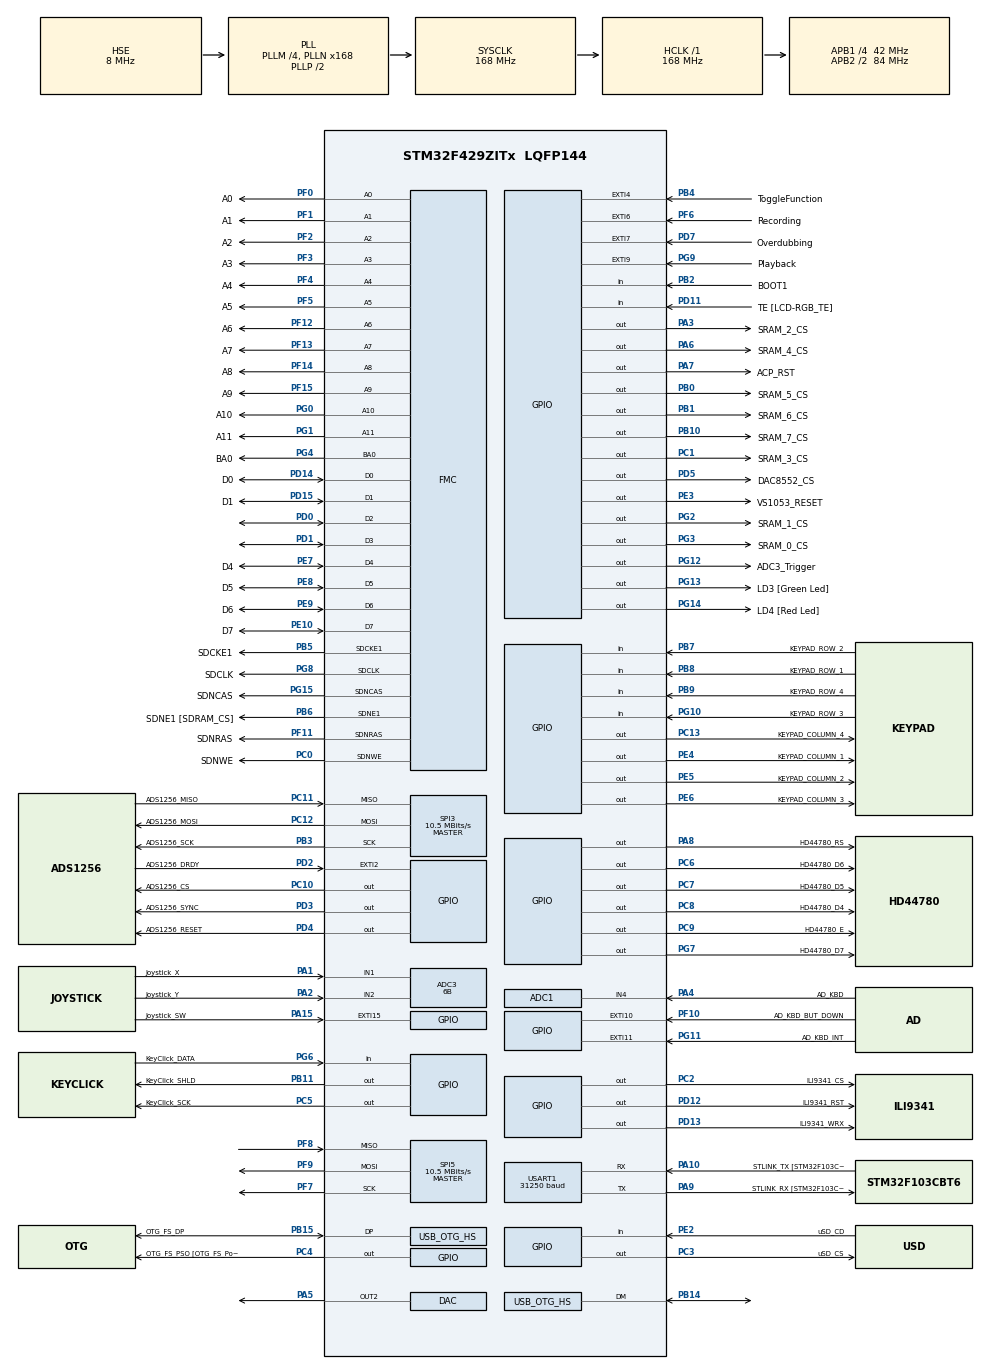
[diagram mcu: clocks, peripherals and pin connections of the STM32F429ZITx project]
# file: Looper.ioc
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ADC1.Channel-0\#ChannelRegularConversion=ADC_CHANNEL_4
ADC1.ClockPrescaler=ADC_CLOCK_SYNC_PCLK_DIV4
ADC1.ContinuousConvMode=DISABLE
ADC1.DMAContinuousRequests=DISABLE
ADC1.DataAlign=ADC_DATAALIGN_RIGHT
ADC1.DiscontinuousConvMode=DISABLE
ADC1.EOCSelection=ADC_EOC_SINGLE_CONV
ADC1.EnableAnalogWatchDog=false
ADC1.ExternalTrigConv=ADC_EXTERNALTRIGCONV_Ext_IT11
ADC1.ExternalTrigConvEdge=ADC_EXTERNALTRIGCONVEDGE_RISING
ADC1.InjNumberOfConversion=0
ADC1.NbrOfConversion=1
ADC1.NbrOfConversionFlag=1
ADC1.Rank-0\#ChannelRegularConversion=1
ADC1.Resolution=ADC_RESOLUTION_6B
ADC1.SamplingTime-0\#ChannelRegularConversion=ADC_SAMPLETIME_480CYCLES
ADC1.ScanConvMode=DISABLE
ADC1.master=1
ADC3.Channel-50\#ChannelRegularConversion=ADC_CHANNEL_1
ADC3.Channel-51\#ChannelRegularConversion=ADC_CHANNEL_2
ADC3.ClockPrescaler=ADC_CLOCK_SYNC_PCLK_DIV4
ADC3.ContinuousConvMode=ENABLE
ADC3.DMAContinuousRequests=ENABLE
ADC3.DataAlign=ADC_DATAALIGN_RIGHT
ADC3.DiscontinuousConvMode=DISABLE
ADC3.EOCSelection=ADC_EOC_SEQ_CONV
ADC3.EnableAnalogWatchDog=false
ADC3.ExternalTrigConv=ADC_SOFTWARE_START
ADC3.ExternalTrigConvEdge=ADC_EXTERNALTRIGCONVEDGE_NONE
ADC3.InjNumberOfConversion=0
ADC3.NbrOfConversion=2
ADC3.NbrOfConversionFlag=1
ADC3.Rank-50\#ChannelRegularConversion=1
ADC3.Rank-51\#ChannelRegularConversion=2
ADC3.Resolution=ADC_RESOLUTION_6B
ADC3.SamplingTime-50\#ChannelRegularConversion=ADC_SAMPLETIME_144CYCLES
ADC3.SamplingTime-51\#ChannelRegularConversion=ADC_SAMPLETIME_144CYCLES
ADC3.ScanConvMode=ENABLE
DAC.DAC_Trigger2=DAC_TRIGGER_T8_TRGO
Dma.ADC3.3.Direction=DMA_PERIPH_TO_MEMORY
Dma.ADC3.3.FIFOMode=DMA_FIFOMODE_DISABLE
Dma.ADC3.3.Instance=DMA2_Stream1
Dma.ADC3.3.MemDataAlignment=DMA_MDATAALIGN_WORD
Dma.ADC3.3.MemInc=DMA_MINC_ENABLE
Dma.ADC3.3.Mode=DMA_CIRCULAR
Dma.ADC3.3.PeriphDataAlignment=DMA_PDATAALIGN_WORD
Dma.ADC3.3.PeriphInc=DMA_PINC_DISABLE
Dma.ADC3.3.Priority=DMA_PRIORITY_MEDIUM
Dma.DAC2.0.Direction=DMA_MEMORY_TO_PERIPH
Dma.DAC2.0.FIFOMode=DMA_FIFOMODE_DISABLE
Dma.DAC2.0.Instance=DMA1_Stream6
Dma.DAC2.0.MemDataAlignment=DMA_MDATAALIGN_HALFWORD
Dma.DAC2.0.MemInc=DMA_MINC_ENABLE
Dma.DAC2.0.Mode=DMA_CIRCULAR
Dma.DAC2.0.PeriphDataAlignment=DMA_PDATAALIGN_HALFWORD
Dma.DAC2.0.PeriphInc=DMA_PINC_DISABLE
Dma.DAC2.0.Priority=DMA_PRIORITY_HIGH
Dma.Request0=DAC2
Dma.Request1=SPI5_RX
Dma.Request2=SPI5_TX
Dma.Request3=ADC3
Dma.SPI5_RX.1.Direction=DMA_PERIPH_TO_MEMORY
Dma.SPI5_RX.1.FIFOMode=DMA_FIFOMODE_ENABLE
Dma.SPI5_RX.1.FIFOThreshold=DMA_FIFO_THRESHOLD_1QUARTERFULL
Dma.SPI5_RX.1.Instance=DMA2_Stream3
Dma.SPI5_RX.1.MemBurst=DMA_MBURST_SINGLE
Dma.SPI5_RX.1.MemDataAlignment=DMA_MDATAALIGN_BYTE
Dma.SPI5_RX.1.MemInc=DMA_MINC_ENABLE
Dma.SPI5_RX.1.Mode=DMA_NORMAL
Dma.SPI5_RX.1.PeriphBurst=DMA_PBURST_SINGLE
Dma.SPI5_RX.1.PeriphDataAlignment=DMA_PDATAALIGN_BYTE
Dma.SPI5_RX.1.PeriphInc=DMA_PINC_DISABLE
Dma.SPI5_RX.1.Priority=DMA_PRIORITY_MEDIUM
Dma.SPI5_TX.2.Direction=DMA_MEMORY_TO_PERIPH
Dma.SPI5_TX.2.FIFOMode=DMA_FIFOMODE_ENABLE
Dma.SPI5_TX.2.FIFOThreshold=DMA_FIFO_THRESHOLD_1QUARTERFULL
Dma.SPI5_TX.2.Instance=DMA2_Stream4
Dma.SPI5_TX.2.MemBurst=DMA_MBURST_SINGLE
Dma.SPI5_TX.2.MemDataAlignment=DMA_MDATAALIGN_BYTE
Dma.SPI5_TX.2.MemInc=DMA_MINC_ENABLE
Dma.SPI5_TX.2.Mode=DMA_NORMAL
Dma.SPI5_TX.2.PeriphBurst=DMA_PBURST_SINGLE
Dma.SPI5_TX.2.PeriphDataAlignment=DMA_PDATAALIGN_BYTE
Dma.SPI5_TX.2.PeriphInc=DMA_PINC_DISABLE
Dma.SPI5_TX.2.Priority=DMA_PRIORITY_MEDIUM
Mcu.Family=STM32F4
Mcu.Name=STM32F429ZITx
Mcu.Package=LQFP144
NVIC.ADC_IRQn=true\:3\:0\:true\:false\:true\:true
NVIC.DMA1_Stream6_IRQn=true\:1\:2\:true\:false\:true\:false
NVIC.DMA2_Stream1_IRQn=true\:1\:3\:true\:false\:true\:false
NVIC.DMA2_Stream3_IRQn=true\:3\:0\:true\:false\:true\:false
NVIC.DMA2_Stream4_IRQn=true\:3\:2\:true\:false\:true\:false
NVIC.EXTI15_10_IRQn=true\:0\:1\:false\:false\:true\:true
NVIC.EXTI2_IRQn=true\:0\:1\:true\:false\:true\:true
NVIC.EXTI4_IRQn=true\:2\:3\:true\:false\:true\:true
NVIC.EXTI9_5_IRQn=true\:2\:3\:true\:false\:true\:true
NVIC.OTG_HS_IRQn=true\:0\:0\:false\:false\:true\:false
NVIC.PVD_IRQn=true\:0\:0\:false\:false\:true\:true
NVIC.PriorityGroup=NVIC_PRIORITYGROUP_2
NVIC.TIM1_BRK_TIM9_IRQn=true\:2\:2\:true\:false\:true\:true
NVIC.TIM2_IRQn=true\:3\:2\:true\:false\:true\:true
NVIC.TIM4_IRQn=true\:3\:3\:true\:false\:true\:true
NVIC.TIM8_UP_TIM13_IRQn=true\:0\:0\:false\:false\:true\:true
PA1.GPIO_Label=Joystick_X
PA1.Signal=ADCx_IN1
PA10.GPIO_Label=STLINK_TX [STM32F103CBT6_PA2]
PA10.Mode=Multiprocessor_communication
PA10.Signal=USART1_RX
PA11.GPIO_Speed=GPIO_SPEED_FREQ_HIGH
PA11.Signal=USB_OTG_FS_DM
PA13.GPIO_Label=SWDIO
PA13.Signal=SYS_JTMS-SWDIO
PA14.GPIO_Label=SWCLK
PA14.Signal=SYS_JTCK-SWCLK
PA15.GPIO_Label=Joystick_SW
PA15.GPIO_ModeDefaultEXTI=GPIO_MODE_IT_FALLING
PA15.Signal=GPXTI15
PA2.GPIO_Label=Joystick_Y
PA2.Signal=ADCx_IN2
PA3.GPIO_Label=SRAM_2_CS
PA3.GPIO_Speed=GPIO_SPEED_FREQ_HIGH
PA3.PinState=GPIO_PIN_SET
PA3.Signal=GPIO_Output
PA4.GPIO_Label=AD_KBD
PA4.Signal=ADCx_IN4
PA5.Signal=COMP_DAC2_group
PA6.GPIO_Label=SRAM_4_CS
PA6.GPIO_Speed=GPIO_SPEED_FREQ_HIGH
PA6.PinState=GPIO_PIN_SET
PA6.Signal=GPIO_Output
PA7.GPIO_Label=ACP_RST
PA7.GPIO_Mode=GPIO_MODE_OUTPUT_PP
PA7.GPIO_PuPd=GPIO_NOPULL
PA7.GPIO_Speed=GPIO_SPEED_FREQ_LOW
PA7.Signal=GPIO_Output
PA8.GPIO_Label=HD44780_RS
PA8.GPIO_Speed=GPIO_SPEED_FREQ_MEDIUM
PA8.PinState=GPIO_PIN_SET
PA8.Signal=GPIO_Output
PA9.GPIO_Label=STLINK_RX [STM32F103CBT6_PA3]
PA9.Mode=Multiprocessor_communication
PA9.Signal=USART1_TX
PB0.GPIO_Label=SRAM_5_CS
PB0.GPIO_Speed=GPIO_SPEED_FREQ_HIGH
PB0.PinState=GPIO_PIN_SET
PB0.Signal=GPIO_Output
PB1.GPIO_Label=SRAM_6_CS
PB1.GPIO_Speed=GPIO_SPEED_FREQ_HIGH
PB1.PinState=GPIO_PIN_SET
PB1.Signal=GPIO_Output
PB10.GPIO_Label=SRAM_7_CS
PB10.GPIO_Speed=GPIO_SPEED_FREQ_HIGH
PB10.PinState=GPIO_PIN_SET
PB10.Signal=GPIO_Output
PB11.GPIO_Label=KeyClick_SHLD
PB11.Signal=GPIO_Output
PB12.GPIO_Label=OTG_FS_ID
PB12.GPIO_Mode=GPIO_MODE_AF_PP
PB12.GPIO_PuPd=GPIO_NOPULL
PB12.GPIO_Speed=GPIO_SPEED_FREQ_LOW
PB12.Signal=USB_OTG_HS_ID
PB13.GPIO_Label=VBUS_FS
PB13.GPIO_Mode=GPIO_MODE_INPUT
PB13.GPIO_PuPd=GPIO_NOPULL
PB13.Signal=USB_OTG_HS_VBUS
PB14.Mode=Device_Only_FS
PB14.Signal=USB_OTG_HS_DM
PB15.GPIO_Label=OTG_FS_DP
PB15.GPIO_Mode=GPIO_MODE_AF_PP
PB15.GPIO_PuPd=GPIO_NOPULL
PB15.GPIO_Speed=GPIO_SPEED_FREQ_LOW
PB15.Mode=Device_Only_FS
PB15.Signal=USB_OTG_HS_DP
PB2/BOOT1.GPIO_Label=BOOT1
PB2/BOOT1.GPIO_Mode=GPIO_MODE_INPUT
PB2/BOOT1.GPIO_PuPd=GPIO_NOPULL
PB2/BOOT1.Signal=GPIO_Input
PB3.GPIO_Label=ADS1256_SCK
PB3.GPIO_Speed=GPIO_SPEED_FREQ_VERY_HIGH
PB3.Mode=Full_Duplex_Master
PB3.Signal=SPI3_SCK
PB4.GPIO_Label=ToggleFunction
PB4.GPIO_ModeDefaultEXTI=GPIO_MODE_IT_FALLING
PB4.Signal=GPXTI4
PB5.GPIO_Label=SDCKE1
PB5.GPIO_Mode=GPIO_MODE_AF_PP
PB5.GPIO_PuPd=GPIO_NOPULL
PB5.GPIO_Speed=GPIO_SPEED_FREQ_VERY_HIGH
PB5.Mode=SdramChipSelect2_2
PB5.Signal=FMC_SDCKE1
PB6.GPIO_Label=SDNE1 [SDRAM_CS]
PB6.GPIO_Mode=GPIO_MODE_AF_PP
PB6.GPIO_PuPd=GPIO_NOPULL
PB6.GPIO_Speed=GPIO_SPEED_FREQ_VERY_HIGH
PB6.Mode=SdramChipSelect2_2
PB6.Signal=FMC_SDNE1
PB7.GPIO_Label=KEYPAD_ROW_2
PB7.GPIO_PuPd=GPIO_PULLUP
PB7.Signal=GPIO_Input
PB8.GPIO_Label=KEYPAD_ROW_1
PB8.GPIO_PuPd=GPIO_PULLUP
PB8.Signal=GPIO_Input
PB9.GPIO_Label=KEYPAD_ROW_4
PB9.GPIO_PuPd=GPIO_PULLUP
PB9.Signal=GPIO_Input
PC0.GPIO_Label=SDNWE
PC0.GPIO_Mode=GPIO_MODE_AF_PP
PC0.GPIO_PuPd=GPIO_NOPULL
PC0.GPIO_Speed=GPIO_SPEED_FREQ_VERY_HIGH
PC0.Signal=FMC_SDNWE
PC1.GPIO_Label=SRAM_3_CS
PC1.Signal=GPIO_Output
PC10.GPIO_Label=ADS1256_CS
PC10.GPIO_Speed=GPIO_SPEED_FREQ_HIGH
PC10.PinState=GPIO_PIN_SET
PC10.Signal=GPIO_Output
PC11.GPIO_Label=ADS1256_MISO
PC11.GPIO_Speed=GPIO_SPEED_FREQ_VERY_HIGH
PC11.Mode=Full_Duplex_Master
PC11.Signal=SPI3_MISO
PC12.GPIO_Label=ADS1256_MOSI
PC12.GPIO_Speed=GPIO_SPEED_FREQ_VERY_HIGH
PC12.Mode=Full_Duplex_Master
PC12.Signal=SPI3_MOSI
PC13.GPIO_Label=KEYPAD_COLUMN_4
PC13.Signal=GPIO_Output
PC14/OSC32_IN.GPIO_Label=PC14-OSC32_IN
PC14/OSC32_IN.Signal=RCC_OSC32_IN
PC15/OSC32_OUT.GPIO_Label=PC15-OSC32_OUT
PC15/OSC32_OUT.Signal=RCC_OSC32_OUT
PC2.GPIO_Label=ILI9341_CS
PC2.Signal=GPIO_Output
PC3.GPIO_Label=uSD_CS
PC3.GPIO_Speed=GPIO_SPEED_FREQ_HIGH
PC3.PinState=GPIO_PIN_SET
PC3.Signal=GPIO_Output
PC4.GPIO_Label=OTG_FS_PSO [OTG_FS_PowerSwitchOn]
PC4.GPIO_Mode=GPIO_MODE_OUTPUT_PP
PC4.GPIO_PuPd=GPIO_NOPULL
PC4.GPIO_Speed=GPIO_SPEED_FREQ_LOW
PC4.Signal=GPIO_Output
PC5.GPIO_Label=KeyClick_SCK
PC5.GPIO_Speed=GPIO_SPEED_FREQ_HIGH
PC5.PinState=GPIO_PIN_SET
PC5.Signal=GPIO_Output
PC6.GPIO_Label=HD44780_D6
PC6.GPIO_Speed=GPIO_SPEED_FREQ_MEDIUM
PC6.PinState=GPIO_PIN_SET
PC6.Signal=GPIO_Output
PC7.GPIO_Label=HD44780_D5
PC7.GPIO_Speed=GPIO_SPEED_FREQ_MEDIUM
PC7.PinState=GPIO_PIN_SET
PC7.Signal=GPIO_Output
PC8.GPIO_Label=HD44780_D4
PC8.GPIO_Speed=GPIO_SPEED_FREQ_MEDIUM
PC8.PinState=GPIO_PIN_SET
PC8.Signal=GPIO_Output
PC9.GPIO_Label=HD44780_E
PC9.GPIO_Speed=GPIO_SPEED_FREQ_MEDIUM
PC9.PinState=GPIO_PIN_SET
PC9.Signal=GPIO_Output
PD0.Signal=FMC_D2_DA2
PD1.Signal=FMC_D3_DA3
PD10.GPIO_Label=D15
PD10.GPIO_Mode=GPIO_MODE_AF_PP
PD10.GPIO_PuPd=GPIO_NOPULL
PD10.GPIO_Speed=GPIO_SPEED_FREQ_VERY_HIGH
PD10.Signal=FMC_D15_DA15
PD11.GPIO_Label=TE [LCD-RGB_TE]
PD11.GPIO_Mode=GPIO_MODE_INPUT
PD11.GPIO_PuPd=GPIO_NOPULL
PD11.Signal=GPIO_Input
PD12.GPIO_Label=ILI9341_RST
PD12.GPIO_Mode=GPIO_MODE_OUTPUT_PP
PD12.GPIO_PuPd=GPIO_NOPULL
PD12.GPIO_Speed=GPIO_SPEED_FREQ_LOW
PD12.Signal=GPIO_Output
PD13.GPIO_Label=ILI9341_WRX
PD13.GPIO_Mode=GPIO_MODE_OUTPUT_PP
PD13.GPIO_PuPd=GPIO_NOPULL
PD13.GPIO_Speed=GPIO_SPEED_FREQ_LOW
PD13.Signal=GPIO_Output
PD14.GPIO_Label=D0
PD14.GPIO_Mode=GPIO_MODE_AF_PP
PD14.GPIO_PuPd=GPIO_NOPULL
PD14.GPIO_Speed=GPIO_SPEED_FREQ_VERY_HIGH
PD14.Signal=FMC_D0_DA0
PD15.GPIO_Label=D1
PD15.GPIO_Mode=GPIO_MODE_AF_PP
PD15.GPIO_PuPd=GPIO_NOPULL
PD15.GPIO_Speed=GPIO_SPEED_FREQ_VERY_HIGH
PD15.Signal=FMC_D1_DA1
PD2.GPIO_Label=ADS1256_DRDY
PD2.GPIO_ModeDefaultEXTI=GPIO_MODE_IT_FALLING
PD2.GPIO_PuPd=GPIO_PULLUP
PD2.Signal=GPXTI2
PD3.GPIO_Label=ADS1256_SYNC
PD3.GPIO_Speed=GPIO_SPEED_FREQ_HIGH
PD3.PinState=GPIO_PIN_SET
PD3.Signal=GPIO_Output
PD4.GPIO_Label=ADS1256_RESET
PD4.GPIO_Speed=GPIO_SPEED_FREQ_HIGH
PD4.PinState=GPIO_PIN_SET
PD4.Signal=GPIO_Output
PD5.GPIO_Label=DAC8552_CS
PD5.Signal=GPIO_Output
PD6.GPIO_Label=B2
PD6.GPIO_Mode=GPIO_MODE_AF_PP
PD6.GPIO_PuPd=GPIO_NOPULL
PD6.GPIO_Speed=GPIO_SPEED_FREQ_LOW
PD6.Signal=LTDC_B2
PD7.GPIO_Label=Overdubbing
PD7.GPIO_ModeDefaultEXTI=GPIO_MODE_IT_FALLING
PD7.Signal=GPXTI7
PE1.GPIO_Label=NBL1 [SDRAM_UDQM]
PE1.GPIO_Mode=GPIO_MODE_AF_PP
PE1.GPIO_PuPd=GPIO_NOPULL
PE1.GPIO_Speed=GPIO_SPEED_FREQ_VERY_HIGH
PE1.Signal=FMC_NBL1
PE10.GPIO_Label=D7
PE10.GPIO_Mode=GPIO_MODE_AF_PP
PE10.GPIO_PuPd=GPIO_NOPULL
PE10.GPIO_Speed=GPIO_SPEED_FREQ_VERY_HIGH
PE10.Signal=FMC_D7_DA7
PE11.GPIO_Label=D8
PE11.GPIO_Mode=GPIO_MODE_AF_PP
PE11.GPIO_PuPd=GPIO_NOPULL
PE11.GPIO_Speed=GPIO_SPEED_FREQ_VERY_HIGH
PE11.Signal=FMC_D8_DA8
PE12.GPIO_Label=D9
PE12.GPIO_Mode=GPIO_MODE_AF_PP
PE12.GPIO_PuPd=GPIO_NOPULL
PE12.GPIO_Speed=GPIO_SPEED_FREQ_VERY_HIGH
PE12.Signal=FMC_D9_DA9
PE13.GPIO_Label=D10
PE13.GPIO_Mode=GPIO_MODE_AF_PP
PE13.GPIO_PuPd=GPIO_NOPULL
PE13.GPIO_Speed=GPIO_SPEED_FREQ_VERY_HIGH
PE13.Signal=FMC_D10_DA10
PE14.GPIO_Label=D11
PE14.GPIO_Mode=GPIO_MODE_AF_PP
PE14.GPIO_PuPd=GPIO_NOPULL
PE14.GPIO_Speed=GPIO_SPEED_FREQ_VERY_HIGH
PE14.Signal=FMC_D11_DA11
PE15.GPIO_Label=D12
PE15.GPIO_Mode=GPIO_MODE_AF_PP
PE15.GPIO_PuPd=GPIO_NOPULL
PE15.GPIO_Speed=GPIO_SPEED_FREQ_VERY_HIGH
PE15.Signal=FMC_D12_DA12
PE2.GPIO_Label=uSD_CD
PE2.GPIO_PuPd=GPIO_PULLUP
PE2.Signal=GPIO_Input
PE3.GPIO_Label=VS1053_RESET
PE3.GPIO_Speed=GPIO_SPEED_FREQ_MEDIUM
PE3.PinState=GPIO_PIN_SET
PE3.Signal=GPIO_Output
PE4.GPIO_Label=KEYPAD_COLUMN_1
PE4.Signal=GPIO_Output
PE5.GPIO_Label=KEYPAD_COLUMN_2
PE5.Signal=GPIO_Output
PE6.GPIO_Label=KEYPAD_COLUMN_3
PE6.Signal=GPIO_Output
PE7.GPIO_Label=D4
PE7.GPIO_Mode=GPIO_MODE_AF_PP
PE7.GPIO_PuPd=GPIO_NOPULL
PE7.GPIO_Speed=GPIO_SPEED_FREQ_VERY_HIGH
PE7.Signal=FMC_D4_DA4
PE8.GPIO_Label=D5
PE8.GPIO_Mode=GPIO_MODE_AF_PP
PE8.GPIO_PuPd=GPIO_NOPULL
PE8.GPIO_Speed=GPIO_SPEED_FREQ_VERY_HIGH
PE8.Signal=FMC_D5_DA5
PE9.GPIO_Label=D6
PE9.GPIO_Mode=GPIO_MODE_AF_PP
PE9.GPIO_PuPd=GPIO_NOPULL
PE9.GPIO_Speed=GPIO_SPEED_FREQ_VERY_HIGH
PE9.Signal=FMC_D6_DA6
PF0.GPIO_Label=A0
PF0.GPIO_Mode=GPIO_MODE_AF_PP
PF0.GPIO_PuPd=GPIO_NOPULL
PF0.GPIO_Speed=GPIO_SPEED_FREQ_VERY_HIGH
PF0.Signal=FMC_A0
PF1.GPIO_Label=A1
PF1.GPIO_Mode=GPIO_MODE_AF_PP
PF1.GPIO_PuPd=GPIO_NOPULL
PF1.GPIO_Speed=GPIO_SPEED_FREQ_VERY_HIGH
PF1.Signal=FMC_A1
PF10.GPIO_Label=AD_KBD_BUT_DOWN
PF10.GPIO_ModeDefaultEXTI=GPIO_MODE_IT_FALLING
PF10.Signal=GPXTI10
PF11.GPIO_Label=SDNRAS
PF11.GPIO_Mode=GPIO_MODE_AF_PP
PF11.GPIO_PuPd=GPIO_NOPULL
PF11.GPIO_Speed=GPIO_SPEED_FREQ_VERY_HIGH
PF11.Signal=FMC_SDNRAS
PF12.GPIO_Label=A6
PF12.GPIO_Mode=GPIO_MODE_AF_PP
PF12.GPIO_PuPd=GPIO_NOPULL
PF12.GPIO_Speed=GPIO_SPEED_FREQ_VERY_HIGH
PF12.Signal=FMC_A6
PF13.GPIO_Label=A7
PF13.GPIO_Mode=GPIO_MODE_AF_PP
PF13.GPIO_PuPd=GPIO_NOPULL
PF13.GPIO_Speed=GPIO_SPEED_FREQ_VERY_HIGH
PF13.Signal=FMC_A7
PF14.GPIO_Label=A8
PF14.GPIO_Mode=GPIO_MODE_AF_PP
PF14.GPIO_PuPd=GPIO_NOPULL
PF14.GPIO_Speed=GPIO_SPEED_FREQ_VERY_HIGH
PF14.Signal=FMC_A8
PF15.GPIO_Label=A9
PF15.GPIO_Mode=GPIO_MODE_AF_PP
PF15.GPIO_PuPd=GPIO_NOPULL
PF15.GPIO_Speed=GPIO_SPEED_FREQ_VERY_HIGH
PF15.Signal=FMC_A9
PF2.GPIO_Label=A2
PF2.GPIO_Mode=GPIO_MODE_AF_PP
PF2.GPIO_PuPd=GPIO_NOPULL
PF2.GPIO_Speed=GPIO_SPEED_FREQ_VERY_HIGH
PF2.Signal=FMC_A2
PF3.GPIO_Label=A3
PF3.GPIO_Mode=GPIO_MODE_AF_PP
PF3.GPIO_PuPd=GPIO_NOPULL
PF3.GPIO_Speed=GPIO_SPEED_FREQ_VERY_HIGH
PF3.Signal=FMC_A3
PF4.GPIO_Label=A4
PF4.GPIO_Mode=GPIO_MODE_AF_PP
PF4.GPIO_PuPd=GPIO_NOPULL
PF4.GPIO_Speed=GPIO_SPEED_FREQ_VERY_HIGH
PF4.Signal=FMC_A4
PF5.GPIO_Label=A5
PF5.GPIO_Mode=GPIO_MODE_AF_PP
PF5.GPIO_PuPd=GPIO_NOPULL
PF5.GPIO_Speed=GPIO_SPEED_FREQ_VERY_HIGH
PF5.Signal=FMC_A5
PF6.GPIO_Label=Recording
PF6.GPIO_ModeDefaultEXTI=GPIO_MODE_IT_FALLING
PF6.Signal=GPXTI6
PF7.GPIO_Speed=GPIO_SPEED_FREQ_HIGH
PF7.Mode=Full_Duplex_Master
PF7.Signal=SPI5_SCK
PF8.GPIO_Speed=GPIO_SPEED_FREQ_HIGH
PF8.Mode=Full_Duplex_Master
PF8.Signal=SPI5_MISO
PF9.GPIO_Speed=GPIO_SPEED_FREQ_HIGH
PF9.Mode=Full_Duplex_Master
PF9.Signal=SPI5_MOSI
PG0.GPIO_Label=A10
PG0.GPIO_Mode=GPIO_MODE_AF_PP
PG0.GPIO_PuPd=GPIO_NOPULL
PG0.GPIO_Speed=GPIO_SPEED_FREQ_VERY_HIGH
PG0.Signal=FMC_A10
PG1.GPIO_Label=A11
PG1.GPIO_Mode=GPIO_MODE_AF_PP
PG1.GPIO_PuPd=GPIO_NOPULL
PG1.GPIO_Speed=GPIO_SPEED_FREQ_VERY_HIGH
PG1.Signal=FMC_A11
PG10.GPIO_Label=KEYPAD_ROW_3
PG10.GPIO_PuPd=GPIO_PULLUP
PG10.Signal=GPIO_Input
PG11.GPIO_Label=AD_KBD_INT
PG11.Signal=GPXTI11
PG12.GPIO_Label=ADC3_Trigger
PG12.Signal=GPIO_Output
PG13.GPIO_Label=LD3 [Green Led]
PG13.GPIO_Mode=GPIO_MODE_OUTPUT_PP
PG13.GPIO_PuPd=GPIO_NOPULL
PG13.GPIO_Speed=GPIO_SPEED_FREQ_LOW
PG13.Signal=GPIO_Output
PG14.GPIO_Label=LD4 [Red Led]
PG14.GPIO_Mode=GPIO_MODE_OUTPUT_PP
PG14.GPIO_PuPd=GPIO_NOPULL
PG14.GPIO_Speed=GPIO_SPEED_FREQ_LOW
PG14.Signal=GPIO_Output
PG15.GPIO_Label=SDNCAS
PG15.GPIO_Mode=GPIO_MODE_AF_PP
PG15.GPIO_PuPd=GPIO_NOPULL
PG15.GPIO_Speed=GPIO_SPEED_FREQ_VERY_HIGH
PG15.Signal=FMC_SDNCAS
PG2.GPIO_Label=SRAM_1_CS
PG2.Signal=GPIO_Output
PG3.GPIO_Label=SRAM_0_CS
PG3.Signal=GPIO_Output
PG4.GPIO_Label=BA0
PG4.GPIO_Mode=GPIO_MODE_AF_PP
PG4.GPIO_PuPd=GPIO_NOPULL
PG4.GPIO_Speed=GPIO_SPEED_FREQ_VERY_HIGH
PG4.Signal=FMC_A14_BA0
PG6.GPIO_Label=KeyClick_DATA
PG6.Signal=GPIO_Input
PG7.GPIO_Label=HD44780_D7
PG7.GPIO_Speed=GPIO_SPEED_FREQ_MEDIUM
PG7.PinState=GPIO_PIN_SET
PG7.Signal=GPIO_Output
PG8.GPIO_Label=SDCLK
PG8.GPIO_Mode=GPIO_MODE_AF_PP
PG8.GPIO_PuPd=GPIO_NOPULL
PG8.GPIO_Speed=GPIO_SPEED_FREQ_VERY_HIGH
PG8.Signal=FMC_SDCLK
PG9.GPIO_Label=Playback
PG9.GPIO_ModeDefaultEXTI=GPIO_MODE_IT_FALLING
PG9.Signal=GPXTI9
PH0/OSC_IN.GPIO_Label=PH0-OSC_IN
PH0/OSC_IN.Mode=HSE-External-Oscillator
PH0/OSC_IN.Signal=RCC_OSC_IN
PH1/OSC_OUT.GPIO_Label=PH1-OSC_OUT
PH1/OSC_OUT.Mode=HSE-External-Oscillator
PH1/OSC_OUT.Signal=RCC_OSC_OUT
ProjectManager.HeapSize=0x200
ProjectManager.StackSize=0x400
ProjectManager.TargetToolchain=SW4STM32
RCC.48MHZClocksFreq_Value=48000000
RCC.AHBFreq_Value=168000000
RCC.APB1CLKDivider=RCC_HCLK_DIV4
RCC.APB1Freq_Value=42000000
RCC.APB1TimFreq_Value=84000000
RCC.APB2CLKDivider=RCC_HCLK_DIV2
RCC.APB2Freq_Value=84000000
RCC.APB2TimFreq_Value=168000000
RCC.CortexFreq_Value=168000000
RCC.HCLKFreq_Value=168000000
RCC.HSE_VALUE=8000000
RCC.HSI_VALUE=16000000
RCC.LSE_VALUE=32768
RCC.PLLM=4
RCC.PLLN=168
RCC.PLLQ=7
RCC.PLLSAIN=50
RCC.SYSCLKFreq_VALUE=168000000
RCC.SYSCLKSource=RCC_SYSCLKSOURCE_PLLCLK
RCC.VCOOutputFreq_Value=336000000
SH.ADCx_IN1.0=ADC3_IN1,IN1
SH.ADCx_IN2.0=ADC3_IN2,IN2
SH.ADCx_IN4.0=ADC1_IN4,IN4
SH.COMP_DAC2_group.0=DAC_OUT2,DAC_OUT2
SH.FMC_A0.0=FMC_A0,12b-sda2
SH.FMC_A1.0=FMC_A1,12b-sda2
SH.FMC_A10.0=FMC_A10,12b-sda2
SH.FMC_A11.0=FMC_A11,12b-sda2
SH.FMC_A14_BA0.0=FMC_BA0,TwoSdramBanks2
SH.FMC_A2.0=FMC_A2,12b-sda2
SH.FMC_A3.0=FMC_A3,12b-sda2
SH.FMC_A4.0=FMC_A4,12b-sda2
SH.FMC_A5.0=FMC_A5,12b-sda2
SH.FMC_A6.0=FMC_A6,12b-sda2
SH.FMC_A7.0=FMC_A7,12b-sda2
SH.FMC_A8.0=FMC_A8,12b-sda2
SH.FMC_A9.0=FMC_A9,12b-sda2
SH.FMC_D0_DA0.0=FMC_D0,sd-8b-d2
SH.FMC_D10_DA10.0=FMC_D10
SH.FMC_D11_DA11.0=FMC_D11
SH.FMC_D12_DA12.0=FMC_D12
SH.FMC_D15_DA15.0=FMC_D15
SH.FMC_D1_DA1.0=FMC_D1,sd-8b-d2
SH.FMC_D2_DA2.0=FMC_D2,sd-8b-d2
SH.FMC_D3_DA3.0=FMC_D3,sd-8b-d2
SH.FMC_D4_DA4.0=FMC_D4,sd-8b-d2
SH.FMC_D5_DA5.0=FMC_D5,sd-8b-d2
SH.FMC_D6_DA6.0=FMC_D6,sd-8b-d2
SH.FMC_D7_DA7.0=FMC_D7,sd-8b-d2
SH.FMC_D8_DA8.0=FMC_D8
SH.FMC_D9_DA9.0=FMC_D9
SH.FMC_NBL1.0=FMC_NBL1
SH.FMC_SDCLK.0=FMC_SDCLK,12b-sda2
SH.FMC_SDNCAS.0=FMC_SDNCAS,12b-sda2
SH.FMC_SDNRAS.0=FMC_SDNRAS,12b-sda2
SH.FMC_SDNWE.0=FMC_SDNWE,12b-sda2
SPI3.BaudRatePrescaler=SPI_BAUDRATEPRESCALER_4
SPI3.CLKPhase=SPI_PHASE_2EDGE
SPI3.CLKPolarity=SPI_POLARITY_LOW
SPI3.CalculateBaudRate=10.5 MBits/s
SPI3.Direction=SPI_DIRECTION_2LINES
SPI3.Mode=SPI_MODE_MASTER
SPI3.VirtualType=VM_MASTER
SPI5.BaudRatePrescaler=SPI_BAUDRATEPRESCALER_8
SPI5.CalculateBaudRate=10.5 MBits/s
SPI5.Direction=SPI_DIRECTION_2LINES
SPI5.Mode=SPI_MODE_MASTER
SPI5.VirtualType=VM_MASTER
TIM2.Period=799
TIM2.Prescaler=104
TIM4.Period=299
TIM4.Prescaler=37499
TIM8.Period=27
TIM8.Prescaler=399
TIM8.TIM_MasterOutputTrigger=TIM_TRGO_UPDATE
TIM9.Period=199
TIM9.Prescaler=199
USART1.BaudRate=31250
USART1.VirtualMode=VM_ASYNC
USB_DEVICE.APP_RX_DATA_SIZE-CDC_HS=128
USB_DEVICE.APP_TX_DATA_SIZE-CDC_HS=128
USB_DEVICE.CLASS_NAME_HS=CDC
USB_DEVICE.PRODUCT_STRING_CDC_HS=STM32 Looper
USB_DEVICE.USBD_DEBUG_LEVEL-CDC_HS=0
USB_DEVICE.VirtualMode-CDC_HS=Cdc
USB_DEVICE.VirtualModeHS=Cdc_HS
USB_OTG_HS.VirtualMode-Device_Only_FS=Device_Only_FS
VP_TIM2_VS_ClockSourceINT.Mode=Internal
VP_TIM4_VS_ClockSourceINT.Mode=Internal
VP_TIM8_VS_ClockSourceINT.Mode=Internal
VP_TIM9_VS_ClockSourceINT.Mode=Internal
VP_USB_DEVICE_VS_USB_DEVICE_CDC_HS.Mode=CDC_HS
board=STM32F429I-DISC1

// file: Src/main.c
/**
  ******************************************************************************
  * @file           : main.c
  * @brief          : Main program body
  ******************************************************************************
  * This notice applies to any and all portions of this file
  * that are not between comment pairs USER CODE BEGIN and
  * USER CODE END. Other portions of this file, whether
  * inserted by the user or by software development tools
  * are owned by their respective copyright owners.
  *
  * Copyright (c) 2019 STMicroelectronics International N.V.
  * All rights reserved.
  *
  * Redistribution and use in source and binary forms, with or without
  * modification, are permitted, provided that the following conditions are met:
  *
  * 1. Redistribution of source code must retain the above copyright notice,
  *    this list of conditions and the following disclaimer.
  * 2. Redistributions in binary form must reproduce the above copyright notice,
  *    this list of conditions and the following disclaimer in the documentation
  *    and/or other materials provided with the distribution.
  * 3. Neither the name of STMicroelectronics nor the names of other
  *    contributors to this software may be used to endorse or promote products
  *    derived from this software without specific written permission.
  * 4. This software, including modifications and/or derivative works of this
  *    software, must execute solely and exclusively on microcontroller or
  *    microprocessor devices manufactured by or for STMicroelectronics.
  * 5. Redistribution and use of this software other than as permitted under
  *    this license is void and will automatically terminate your rights under
  *    this license.
  *
  * THIS SOFTWARE IS PROVIDED BY STMICROELECTRONICS AND CONTRIBUTORS "AS IS"
  * AND ANY EXPRESS, IMPLIED OR STATUTORY WARRANTIES, INCLUDING, BUT NOT
  * LIMITED TO, THE IMPLIED WARRANTIES OF MERCHANTABILITY, FITNESS FOR A
  * PARTICULAR PURPOSE AND NON-INFRINGEMENT OF THIRD PARTY INTELLECTUAL PROPERTY
  * RIGHTS ARE DISCLAIMED TO THE FULLEST EXTENT PERMITTED BY LAW. IN NO EVENT
  * SHALL STMICROELECTRONICS OR CONTRIBUTORS BE LIABLE FOR ANY DIRECT, INDIRECT,
  * INCIDENTAL, SPECIAL, EXEMPLARY, OR CONSEQUENTIAL DAMAGES (INCLUDING, BUT NOT
  * LIMITED TO, PROCUREMENT OF SUBSTITUTE GOODS OR SERVICES; LOSS OF USE, DATA,
  * OR PROFITS; OR BUSINESS INTERRUPTION) HOWEVER CAUSED AND ON ANY THEORY OF
  * LIABILITY, WHETHER IN CONTRACT, STRICT LIABILITY, OR TORT (INCLUDING
  * NEGLIGENCE OR OTHERWISE) ARISING IN ANY WAY OUT OF THE USE OF THIS SOFTWARE,
  * EVEN IF ADVISED OF THE POSSIBILITY OF SUCH DAMAGE.
  *
  ******************************************************************************
  */
#include "main.h"
#include "stm32f4xx_hal.h"
#include "adc.h"
#include "dac.h"
#include "dma.h"
#include "spi.h"
#include "tim.h"
#include "usart.h"
#include "usb_device.h"
#include "gpio.h"
#include "fmc.h"

/* USER CODE BEGIN Includes */
#include "tm_stm32_hd44780.h"
#include "ads1256_test.h"
#include "tm_stm32f4_keypad.h"
#include "tm_stm32f4_ili9341.h"
#include "stm32f429i_discovery_sdram.h"
#include "main.h"
#include "midi.h"
#include "menu.h"
#include "drums.h"
#include "string.h"
#include "math.h"
#include "drums.h"
#include "stdlib.h"
#include "audio.h"
#include "spi_flash.h"
#include "spiffs.h"
#include "SRAMDriver.h"
#include "tm_stm32f4_fatfs.h"
#include "memops.h"
#include "usb_device.h"
#include "usbd_core.h"
#include "usbd_cdc_if.h"
#include "joystick.h"
#include "AT45DBXX.h"

#define pi 3.14159
#define LOG_PAGE_SIZE       256
/* USER CODE END Includes */

/* USER CODE BEGIN PV */
/* Private variables ---------------------------------------------------------*/
LooperApplication looper;
uint8_t switches = 0;
char lcdline[30];
/* USER CODE END PV */

void SystemClock_Config(void);

/* USER CODE BEGIN PFP */
/* Private function prototypes -----------------------------------------------*/
static void my_spiffs_mount();

/* USER CODE END PFP */

/* USER CODE BEGIN 0 */

FATFS FatFs;
spiffs fs;
static u8_t spiffs_work_buf[LOG_PAGE_SIZE*2];
static u8_t spiffs_fds[32*4];
static u8_t spiffs_cache_buf[(LOG_PAGE_SIZE+32)*4];

BOOL fs_mounted = FALSE;

TM_KEYPAD_Button_t Keypad_Button;
FUNCTION saveFunction = IDLE;
BOOL Skip_Read_Button = FALSE;
BOOL show_status_line = FALSE;
uint32_t joystick_data[2];
/* USER CODE END 0 */

int main(void)
{
  /* USER CODE BEGIN 1 */

	uint32_t data = 0,bytesWritten = 0;
	HAL_StatusTypeDef status;
	uint8_t at45db[20];

	CoreDebug->DEMCR |= CoreDebug_DEMCR_TRCENA_Msk;
	DWT->CYCCNT = 0;
	DWT->CTRL |= DWT_CTRL_CYCCNTENA_Msk;

  /* USER CODE END 1 */

  /* MCU Configuration----------------------------------------------------------*/

  /* Reset of all peripherals, Initializes the Flash interface and the Systick. */
  HAL_Init();

  /* USER CODE BEGIN Init */
  looper.Function = IDLE;
  looper.TwoChannels = FALSE;
  looper.ch1.Active = TRUE;
  looper.ch1.Monitor = FALSE;
  looper.ch2.Active = FALSE;
  looper.ch2.Monitor = FALSE;
  looper.timeIncrement = 0;
  looper.SampleBytes = 2;
  /* USER CODE END Init */

  /* Configure the system clock */
  SystemClock_Config();

  /* Initialize all configured peripherals */
  MX_GPIO_Init();
  MX_DMA_Init();
  MX_TIM2_Init();
  MX_FMC_Init();
  MX_TIM4_Init();
  MX_SPI3_Init();
  MX_USART1_UART_Init();
  MX_ADC1_Init();
  MX_SPI5_Init();
  MX_DAC_Init();
  MX_TIM8_Init();
  MX_USB_DEVICE_Init();
  MX_TIM9_Init();
  MX_ADC3_Init();
  /* USER CODE BEGIN 2 */
  sFLASH_Init();
  my_spiffs_mount();
  BSP_SDRAM_Init();
  HAL_NVIC_DisableIRQ(EXTI2_IRQn);
  //HAL_GPIO_WritePin(GPIOC,GPIO_PIN_1,GPIO_PIN_SET);
  TM_ILI9341_Init();
  //Rotate LCD for 90 degrees
  TM_ILI9341_Rotate(TM_ILI9341_Orientation_Landscape_1);
  //FIll lcd with color
  TM_ILI9341_Fill(ILI9341_COLOR_MAGENTA);

  status = HAL_TIM_Base_Start_IT(&htim9);

  BSP_LED_Init(LED_GREEN);
  BSP_LED_Init(LED_RED);
  BSP_PB_Init(BUTTON_KEY, BUTTON_MODE_EXTI);

  status = HAL_TIM_Base_Start_IT(&htim4);
  status = HAL_ADC_Start_IT(&hadc1);

  status = HAL_ADC_Start_DMA(&hadc3,joystick_data,2);

  ADS1256_WriteCmd(CMD_RESET);
  ADS1256_WriteCmd(CMD_SDATAC);
  data = ADS1256_ReadChipID();

  ADS1256_CfgADC(ADS1256_GAIN_2, ADS1256_15000SPS);
  ADS1256_SetDiffChannel(0);
  ADS1256_WriteCmd(CMD_SELFCAL);
  ADS1256_WriteCmd(CMD_SELFOCAL);

  HAL_NVIC_EnableIRQ(EXTI2_IRQn);
  ADS1256_WriteCmd(CMD_RDATAC);
  //FATFS_UnLinkDriver(SD_Path);
  TM_KEYPAD_Init();

  setupMidi();
  talkMIDI(0xB0, 0, 0x01); //Default bank GM1

  TM_HD44780_Init(20, 4);
  TM_HD44780_Clear();
  TM_HD44780_Puts(0,0,"Looper");

  InitSRAM();
  menuInit();
  menuShow(0);

  // TODO: write initial rhythm header to SRAM
  SRAM_seekWrite(0,SRAM_SET);
  writeSRAM((unsigned char *)"\0\0\0\0\0\0\0\0\0\0\0\0",12);

  /* USER CODE END 2 */

  /* Infinite loop */
  /* USER CODE BEGIN WHILE */

  while (TRUE)
  {
	  checkSD();
	  if(Skip_Read_Button == FALSE)
		  Keypad_Button = TM_KEYPAD_Read();
	  Skip_Read_Button = FALSE;
	  /* Keypad was pressed */
	  if (Keypad_Button != TM_KEYPAD_Button_NOPRESSED) {/* Keypad is pressed */
		  menuShow(Keypad_Button);

	  }// end of key pressed

	  SHOW_STATUS_LINE();

  /* USER CODE END WHILE */

	}

}

void SystemClock_Config(void)
{

  RCC_OscInitTypeDef RCC_OscInitStruct;
  RCC_ClkInitTypeDef RCC_ClkInitStruct;

    /**Configure the main internal regulator output voltage
    */
  __HAL_RCC_PWR_CLK_ENABLE();

  __HAL_PWR_VOLTAGESCALING_CONFIG(PWR_REGULATOR_VOLTAGE_SCALE1);

    /**Initializes the CPU, AHB and APB busses clocks
    */
  RCC_OscInitStruct.OscillatorType = RCC_OSCILLATORTYPE_HSE;
  RCC_OscInitStruct.HSEState = RCC_HSE_ON;
  RCC_OscInitStruct.PLL.PLLState = RCC_PLL_ON;
  RCC_OscInitStruct.PLL.PLLSource = RCC_PLLSOURCE_HSE;
  RCC_OscInitStruct.PLL.PLLM = 4;
  RCC_OscInitStruct.PLL.PLLN = 168;
  RCC_OscInitStruct.PLL.PLLP = RCC_PLLP_DIV2;
  RCC_OscInitStruct.PLL.PLLQ = 7;
  if (HAL_RCC_OscConfig(&RCC_OscInitStruct) != HAL_OK)
  {
    _Error_Handler(__FILE__, __LINE__);
  }

    /**Initializes the CPU, AHB and APB busses clocks
    */
  RCC_ClkInitStruct.ClockType = RCC_CLOCKTYPE_HCLK|RCC_CLOCKTYPE_SYSCLK
                              |RCC_CLOCKTYPE_PCLK1|RCC_CLOCKTYPE_PCLK2;
  RCC_ClkInitStruct.SYSCLKSource = RCC_SYSCLKSOURCE_PLLCLK;
  RCC_ClkInitStruct.AHBCLKDivider = RCC_SYSCLK_DIV1;
  RCC_ClkInitStruct.APB1CLKDivider = RCC_HCLK_DIV4;
  RCC_ClkInitStruct.APB2CLKDivider = RCC_HCLK_DIV2;

  if (HAL_RCC_ClockConfig(&RCC_ClkInitStruct, FLASH_LATENCY_5) != HAL_OK)
  {
    _Error_Handler(__FILE__, __LINE__);
  }

    /**Configure the Systick interrupt time
    */
  HAL_SYSTICK_Config(HAL_RCC_GetHCLKFreq()/1000);

    /**Configure the Systick
    */
  HAL_SYSTICK_CLKSourceConfig(SYSTICK_CLKSOURCE_HCLK);

  /* SysTick_IRQn interrupt configuration */
  HAL_NVIC_SetPriority(SysTick_IRQn, 0, 0);
}

/* USER CODE BEGIN 4 */
static s32_t my_spiffs_read(u32_t addr, u32_t size, u8_t *dst) {
    sFLASH_ReadBuffer(dst,addr,size);
    return SPIFFS_OK;
  }

  static s32_t my_spiffs_write(u32_t addr, u32_t size, u8_t *src) {
	sFLASH_WriteBuffer(src,addr,size);
    return SPIFFS_OK;
  }

  static s32_t my_spiffs_erase(u32_t addr, u32_t size) {

    return sFLASH_Erase(addr, size);
  }

void my_spiffs_mount() {
    spiffs_config cfg;
    cfg.phys_size = N25Q256A_FLASH_SIZE; // use all spi flash
    cfg.phys_addr = 0; // start spiffs at start of spi flash
    cfg.phys_erase_block = N25Q256A_SECTOR_SIZE; // according to datasheet
    cfg.log_block_size = N25Q256A_SECTOR_SIZE; // let us not complicate things
    cfg.log_page_size = N25Q256A_PAGE_SIZE; // as we said

    cfg.hal_read_f = my_spiffs_read;
    cfg.hal_write_f = my_spiffs_write;
    cfg.hal_erase_f = my_spiffs_erase;

    int res = SPIFFS_mount(&fs,
      &cfg,
      spiffs_work_buf,
      spiffs_fds,
      sizeof(spiffs_fds),
      spiffs_cache_buf,
      sizeof(spiffs_cache_buf),
      0);
    printf("mount res: %i\n", res);
  }

FRESULT open_append (
    FIL* fp,            /* [OUT] File object to create */
    const char* path    /* [IN]  File name to be opened */
)
{
    FRESULT fr;

    /* Opens an existing file. If not exist, creates a new file. */
    fr = f_open(fp, path, FA_WRITE | FA_OPEN_ALWAYS);
    if (fr == FR_OK) {
        /* Seek to end of the file to append data */
        fr = f_lseek(fp, f_size(fp));
        if (fr != FR_OK)
            f_close(fp);
    }
    return fr;
}

void buttonHandler() {
	if(IS_BUT_DOWN(BUT_REC) && HAL_GPIO_ReadPin(Recording_GPIO_Port,Recording_Pin) == GPIO_PIN_SET )
		BUT_UP(BUT_REC);

	if(IS_BUT_DOWN(BUT_PLAY) && HAL_GPIO_ReadPin(Playback_GPIO_Port,Playback_Pin) == GPIO_PIN_SET )
		BUT_UP(BUT_PLAY);

	if(IS_BUT_DOWN(BUT_OVERDUB) && HAL_GPIO_ReadPin(Overdubbing_GPIO_Port,Overdubbing_Pin) == GPIO_PIN_SET )
		BUT_UP(BUT_OVERDUB);

	if(IS_BUT_DOWN(BUT_TOGFUN) && HAL_GPIO_ReadPin(ToggleFunction_GPIO_Port,ToggleFunction_Pin) == GPIO_PIN_SET )
		BUT_UP(BUT_TOGFUN);

	if(IS_BUT_DOWN(BUT_JOYSTICK) && HAL_GPIO_ReadPin(Joystick_SW_GPIO_Port,Joystick_SW_Pin) == GPIO_PIN_SET )
			BUT_UP(BUT_JOYSTICK);
}

void set_function(FUNCTION fun){
	if(looper.Function != fun){
		looper.Function = fun;
		show_status_line = TRUE;
	}
	saveFunction = fun;
}

/* USER CODE END 4 */

void _Error_Handler(char *file, int line)
{
  while(1)
  {
  }
}

/************************ (C) COPYRIGHT STMicroelectronics *****END OF FILE****/
